# PIC32CX5109BZ36048_SL3 register map
Vendor: Microchip Technology; Series: PIC32CXBZ36; File version: 0
CPU: CM4 r0p1, little endian, MPU, FPU, 3 interrupt priority bits, 43 interrupts
Registers are 32-bit, read-write, reset 0x0 unless marked. A register's access mark holds for its fields unless they carry their own. Offsets are from the block's base; [hi:lo] are bit positions; {n}, {i} and the like mark numbered series.

## ROT — Secure Root of Trust Macro
Base 0x44002C00
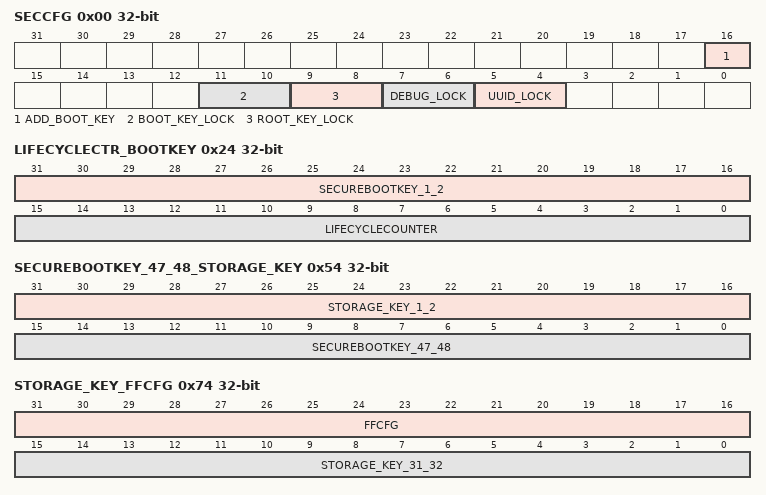
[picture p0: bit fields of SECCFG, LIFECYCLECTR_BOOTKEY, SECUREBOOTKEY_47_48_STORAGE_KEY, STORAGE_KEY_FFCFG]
0x00 SECCFG — Secure Configuration HOLDING REGISTER1,2
  [16] ADD_BOOT_KEY — Additional boot Key bit
  [11:10] BOOT_KEY_LOCK — Lock bits for Secure Boot/OTA Key
    0=BOOT_KEY_NOT_LCK_0 (Secure boot key is not locked); 1=BOOT_KEY_LCK_1 (Secure boot key is locked and cannot be programmed); 2=BOOT_KEY_LCK_2 (Secure boot key is locked and cannot be programmed); 3=BOOT_KEY_LCK_3 (Secure boot key is locked and cannot be programmed)
  [9:8] ROOT_KEY_LOCK — Lock bits for storage root Key
    0=ROOT_KEY_NOT_LCK_0 (Storage root key is not locked); 1=ROOT_KEY_LCK_1 (Storage root key is locked and cannot be programmed); 2=ROOT_KEY_LCK_2 (Storage root key is locked and cannot be programmed); 3=ROOT_KEY_LCK_3 (Storage root key is locked and cannot be programmed)
  [7:6] DEBUG_LOCK — Lock bits for debug/programming
    0=DEBUG_NOT_LCK_0 (Debug is not locked); 1=DEBUG_LCK_1 (Debug is locked); 2=DEBUG_LCK_2 (Debug is locked); 3=DEBUG_LCK_3 (Debug is locked)
  [5:4] UUID_LOCK — Programming lock bits for Unique ID fuses
    0=UUID_NOT_LCK_0 (Unique ID is not locked); 1=UUID_LCK_1 (Unique ID is locked and cannot be programmed); 2=UUID_LCK_2 (Unique ID is locked and cannot be programmed); 3=UUID_LCK_3 (Unique ID is locked and cannot be programmed)
{0x4+4i} ANTIROLLBACKCOUNTER[{i}] (i=0..7)
  [31:0] ANTIROLLBACKCOUNTER — Anti rollback counter bits
0x24 LIFECYCLECTR_BOOTKEY — Life cycle counter and Secure boot key LSB bytes
  [31:16] SECUREBOOTKEY_1_2 — Secure boot key bits
  [15:0] LIFECYCLECOUNTER — Life cycle counter bits
{0x28+4i} SECUREBOOTKEY_3_46[{i}] (i=0..10) — Secure boot key
  [31:0] SECUREBOOTKEY_3_46 — Secure boot key bits
0x54 SECUREBOOTKEY_47_48_STORAGE_KEY — Secure boot key, Storage Key
  [31:16] STORAGE_KEY_1_2 — Storage root key bits
  [15:0] SECUREBOOTKEY_47_48 — Secure boot key bits
{0x58+4i} STORAGE_KEY_3_30[{i}] (i=0..6) — Storage Key
  [31:0] STORAGE_KEY_3_30 — Storage Key bits
0x74 STORAGE_KEY_FFCFG
  [31:16] FFCFG — FFCFG bits
  [15:0] STORAGE_KEY_31_32 — Storage Key bits
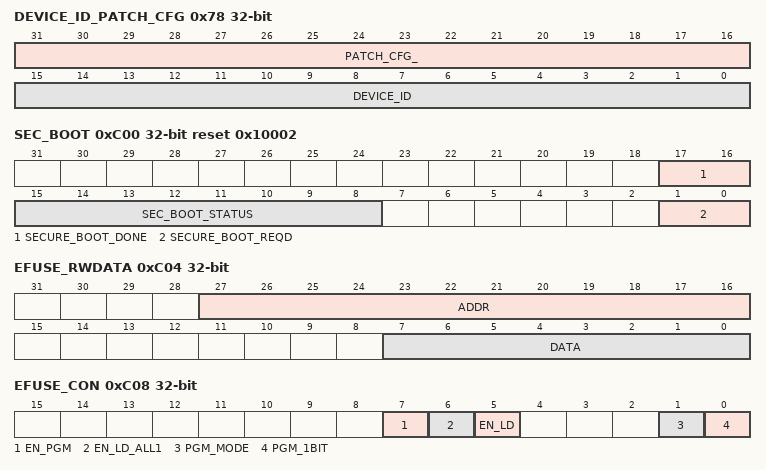
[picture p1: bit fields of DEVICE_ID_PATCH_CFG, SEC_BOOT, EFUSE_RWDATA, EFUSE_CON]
0x78 DEVICE_ID_PATCH_CFG — Device ID and Patch CFG
  [31:16] PATCH_CFG_ — Patch CFG bits
  [15:0] DEVICE_ID — Device ID bits
0x7C PATCH_CFG
  [31:0] PATCH_CFG — Patch CFG bits
{0x80+4i} PATCH_CODE[{i}] (i=0..52)
  [31:0] PATCH_CODE — Patch Code bits
{0x1D8+4i} UUID[{i}] (i=0..3) — Unique ID
  [31:0] UUID — Unique ID bits
0xC00 SEC_BOOT reset 0x10002 — Secure Boot Register
  [17:16] SECURE_BOOT_DONE — Bits to indicate that secure boot is done
    0=SEC_BOOT_DONE_0 (S ecure boot is done); 1=SEC_BOOT_NOT_DONE_1 (S ecure boot is not done); 2=SEC_BOOT_NOT_DONE_2 (S ecure boot is not done); 3=SEC_BOOT_DONE_3 (S ecure boot is done)
  [15:8] SEC_BOOT_STATUS — Bits to indicate that secure boot status
  [1:0] SECURE_BOOT_REQD — Bits to indicate that secure boot is required on the next device reset.
    0=SEC_BOOT_REQD_0 (Secure boot code authentication is required); 1=SEC_BOOT_NOT_REQD_1 (Secure boot code authentication is NOT required); 2=SEC_BOOT_NOT_REQD_2 (Secure boot code authentication is NOT required); 3=SEC_BOOT_REQD_3 (Secure boot code authentication is required)
0xC04 EFUSE_RWDATA
  [27:16] ADDR — eFuse Program/Read Address
  [7:0] DATA — eFuse Program (Write) Data
0xC08 EFUSE_CON — Efuse Configuration Register2
  [7] EN_PGM — eFuse Programming Start bit
    0=EN_PGM_COMPLETED (EFuse Programming operation has completed); 1=EN_PGM_START (Start eFuse Programming operation)
  [6] EN_LD_ALL1 — eFuse Panel Read Start bit for loading into the holding registers
    0=ENLD_ALL1_READ_COMPLETED (EFuse Read operation has completed); 1=ENLD_ALL1_READ_START (Start eFuse Read operation for entire eFuse panel)
  [5] EN_LD — eFuse Word Read Start bit for loading the fuse byte pointed by ADDR field into the holding register
    0=ENLD_READ_COMPLETED (EFuse Read operation has completed); 1=ENLD_READ_START (Start eFuse Read operation for specified eFuse word as addressed in EFUSE_RWDATA register)
  [1] PGM_MODE — eFuse Programming Mode Enable bit
    0=PGM_MODE_DISABLED (EFuse Programming disabled); 1=PGM_MODE_ENABLED (EFuse Programming enabled)
  [0] PGM_1BIT — eFuse CTRL to program 1 bit at a time. Valid only when EN_PGM is set
    0=EFUSE_RW_15_0 (EFuse controller will program EFUSE_RWDATA.DATA[15:0] to the address in EFUSE_RWDATA.ADDR[11:3]); 1=EFUSE_RW_0 (EFuse controller will program EFUSE_RWDATA.DATA[0] to the address in EFUSE_RWDATA.ADDR[11:0])
